AUTOSAR XML (schema 4-3-0)
package /CollisionDetectionBSW/Services/BswM
  impl type ComMModeEnum: compu {0=COMM_NO_COMMUNICATION, 1=COMM_SILENT_COMMUNICATION, 2=COMM_FULL_COMMUNICATION}, implementation-data-type=uint8
  sender receiver interface ComMModeRequestInterface
    data requestedMode: type=ComMModeEnum
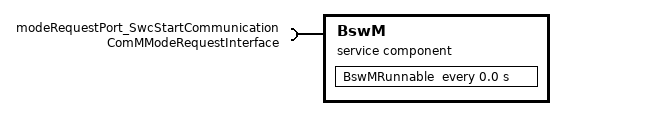
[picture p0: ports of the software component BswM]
  service sw component type BswM
    require port modeRequestPort_SwcStartCommunication: required-interface=ComMModeRequestInterface
    behavior BswMInternalBehavior: handle-termination-and-restart=NO-SUPPORT
      timing event BswMRunnableEvent: start-on-event=BswMRunnable, period=0.0
      runnable BswMRunnable: symbol=BswM_MainFunction
        data-receive-point-by-arguments:
          access dataReceivePoint_BswMRunnable_modeRequestPort_SwcStartCommunication_requestedMode: accessed-variable=modeRequestPort_SwcStartCommunication.requestedMode
  swc implementation BswMComponentImpl: programming-language=C, vendor-id=60, behavior=BswMInternalBehavior
    code-descriptors:
      code src: artifact-descriptors=autosar-engineering-object={short-label=artifactDescriptor, category=artifactDescriptorCategory}
    resource consumption resourceConsumption
